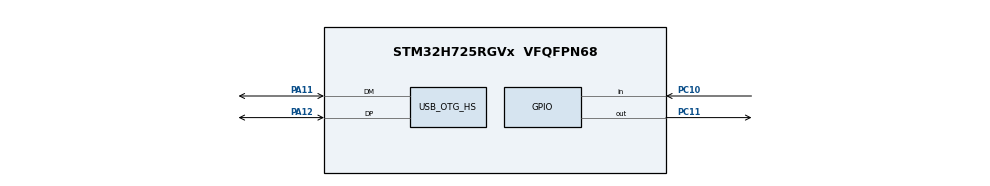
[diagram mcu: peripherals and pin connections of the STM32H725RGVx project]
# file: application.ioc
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Mcu.Family=STM32H7
Mcu.Name=STM32H725RGVx
Mcu.Package=VFQFPN68
NVIC.OTG_HS_IRQn=true\:0\:0\:false\:false\:true\:false\:true\:true
NVIC.PriorityGroup=NVIC_PRIORITYGROUP_4
PA11.Mode=Device_Only_FS
PA11.Signal=USB_OTG_HS_DM
PA12.Mode=Device_Only_FS
PA12.Signal=USB_OTG_HS_DP
PA13(JTMS/SWDIO).Mode=Serial_Wire
PA13(JTMS/SWDIO).Signal=DEBUG_JTMS-SWDIO
PA14(JTCK/SWCLK).Mode=Serial_Wire
PA14(JTCK/SWCLK).Signal=DEBUG_JTCK-SWCLK
PC10.Signal=GPIO_Input
PC11.Signal=GPIO_Output
ProjectManager.HeapSize=0x200
ProjectManager.StackSize=0x400
ProjectManager.TargetToolchain=Makefile
RCC.ADCFreq_Value=48000000
RCC.APB1Freq_Value=128000000
RCC.APB2Freq_Value=128000000
RCC.APB3Freq_Value=128000000
RCC.APB4Freq_Value=128000000
RCC.CortexFreq_Value=512000000
RCC.D1PPRE=RCC_APB3_DIV2
RCC.D2PPRE1=RCC_APB1_DIV2
RCC.D2PPRE2=RCC_APB2_DIV2
RCC.D3PPRE=RCC_APB4_DIV2
RCC.DIVM1=4
RCC.DIVM2=4
RCC.DIVN1=32
RCC.DIVN2=12
RCC.DIVP1=1
RCC.DIVP2=4
RCC.DIVQ1=4
RCC.HCLKFreq_Value=256000000
RCC.HPRE=RCC_HCLK_DIV2
RCC.PLL2FRACN=0
RCC.PLL2_VCI_Range-AdvancedSettings=RCC_PLL2VCIRANGE_0
RCC.PLL3FRACN=0
RCC.PLLFRACN=0
RCC.PLLSourceVirtual=RCC_PLLSOURCE_HSI
RCC.SYSCLKFreq_VALUE=512000000
RCC.SYSCLKSource=RCC_SYSCLKSOURCE_PLLCLK
RCC.Tim1Mul=1
RCC.USBCLockSelection=RCC_USBCLKSOURCE_HSI48
RCC.USBFreq_Value=48000000
USB_DEVICE.CLASS_NAME_HS=DFU
USB_DEVICE.VirtualMode=Dfu
USB_DEVICE.VirtualModeHS=Dfu_HS
USB_OTG_HS.VirtualMode=Device_Only_FS
VP_USB_DEVICE_VS_USB_DEVICE_DFU_HS.Mode=DFU_HS
board=custom

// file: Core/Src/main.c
/* USER CODE BEGIN Header */
/**
  ******************************************************************************
  * @file           : main.c
  * @brief          : Main program body
  ******************************************************************************
  * @attention
  *
  * Copyright (c) 2025 STMicroelectronics.
  * All rights reserved.
  *
  * This software is licensed under terms that can be found in the LICENSE file
  * in the root directory of this software component.
  * If no LICENSE file comes with this software, it is provided AS-IS.
  *
  ******************************************************************************
  */
/* USER CODE END Header */
#include "main.h"
#include "usb_device.h"
#include "gpio.h"

void SystemClock_Config(void);

int main(void)
{

  /* MCU Configuration--------------------------------------------------------*/

  /* Reset of all peripherals, Initializes the Flash interface and the Systick. */
  HAL_Init();

  /* USER CODE BEGIN Init */
  SCB->VTOR = 0x08020000; // shifts vector table for interrupts
  /* USER CODE END Init */

  /* Configure the system clock */
  SystemClock_Config();

  /* Initialize all configured peripherals */
  MX_GPIO_Init();
  MX_USB_DEVICE_Init();

  /* Infinite loop */
  while (1)
  {

  }
}

void SystemClock_Config(void)
{
  RCC_OscInitTypeDef RCC_OscInitStruct = {0};
  RCC_ClkInitTypeDef RCC_ClkInitStruct = {0};

  /** Supply configuration update enable
  */
  HAL_PWREx_ConfigSupply(PWR_DIRECT_SMPS_SUPPLY);

  /** Configure the main internal regulator output voltage
  */
  __HAL_PWR_VOLTAGESCALING_CONFIG(PWR_REGULATOR_VOLTAGE_SCALE0);

  while(!__HAL_PWR_GET_FLAG(PWR_FLAG_VOSRDY)) {}

  /** Initializes the RCC Oscillators according to the specified parameters
  * in the RCC_OscInitTypeDef structure.
  */
  RCC_OscInitStruct.OscillatorType = RCC_OSCILLATORTYPE_HSI48|RCC_OSCILLATORTYPE_HSI;
  RCC_OscInitStruct.HSIState = RCC_HSI_DIV1;
  RCC_OscInitStruct.HSICalibrationValue = RCC_HSICALIBRATION_DEFAULT;
  RCC_OscInitStruct.HSI48State = RCC_HSI48_ON;
  RCC_OscInitStruct.PLL.PLLState = RCC_PLL_ON;
  RCC_OscInitStruct.PLL.PLLSource = RCC_PLLSOURCE_HSI;
  RCC_OscInitStruct.PLL.PLLM = 4;
  RCC_OscInitStruct.PLL.PLLN = 32;
  RCC_OscInitStruct.PLL.PLLP = 1;
  RCC_OscInitStruct.PLL.PLLQ = 4;
  RCC_OscInitStruct.PLL.PLLR = 2;
  RCC_OscInitStruct.PLL.PLLRGE = RCC_PLL1VCIRANGE_3;
  RCC_OscInitStruct.PLL.PLLVCOSEL = RCC_PLL1VCOWIDE;
  RCC_OscInitStruct.PLL.PLLFRACN = 0;
  if (HAL_RCC_OscConfig(&RCC_OscInitStruct) != HAL_OK)
  {
    Error_Handler();
  }

  /** Initializes the CPU, AHB and APB buses clocks
  */
  RCC_ClkInitStruct.ClockType = RCC_CLOCKTYPE_HCLK|RCC_CLOCKTYPE_SYSCLK
                              |RCC_CLOCKTYPE_PCLK1|RCC_CLOCKTYPE_PCLK2
                              |RCC_CLOCKTYPE_D3PCLK1|RCC_CLOCKTYPE_D1PCLK1;
  RCC_ClkInitStruct.SYSCLKSource = RCC_SYSCLKSOURCE_PLLCLK;
  RCC_ClkInitStruct.SYSCLKDivider = RCC_SYSCLK_DIV1;
  RCC_ClkInitStruct.AHBCLKDivider = RCC_HCLK_DIV2;
  RCC_ClkInitStruct.APB3CLKDivider = RCC_APB3_DIV2;
  RCC_ClkInitStruct.APB1CLKDivider = RCC_APB1_DIV2;
  RCC_ClkInitStruct.APB2CLKDivider = RCC_APB2_DIV2;
  RCC_ClkInitStruct.APB4CLKDivider = RCC_APB4_DIV2;

  if (HAL_RCC_ClockConfig(&RCC_ClkInitStruct, FLASH_LATENCY_3) != HAL_OK)
  {
    Error_Handler();
  }
}

void Error_Handler(void)
{
  __disable_irq();
  while (1)
  {
  }
}
